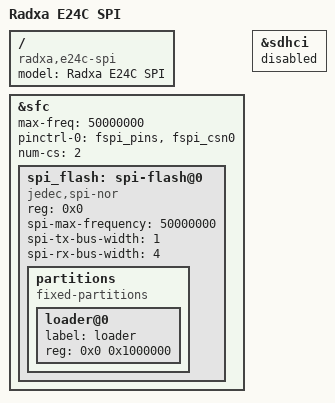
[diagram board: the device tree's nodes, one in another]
// SPDX-License-Identifier: (GPL-2.0+ OR MIT)
/*
 * Copyright (c) 2022 Rockchip Electronics Co., Ltd.
 * Copyright (c) 2024 Radxa Computer (Shenzhen) Co., Ltd.
 *
 */

// From https://github.com/radxa/kernel/blob/linux-6.1-stan-rkr5.1/arch/arm64/boot/dts/rockchip/rk3528-radxa-e24c-spi.dts @8582469f117fdfd5d1ab88fa7e4e15c3b714bf24

/dts-v1/;

#include "rk3528-radxa-e24c.dts"

/ {
	model = "Radxa E24C SPI";
	compatible = "radxa,e24c-spi", "radxa,e24c", "radxa,rock-2", "rockchip,rk3528a";
};

&sfc {
	status = "okay";
	max-freq = <50000000>;
	#address-cells = <1>;
	#size-cells = <0>;
	pinctrl-names = "default";
	pinctrl-0 = <&fspi_pins &fspi_csn0>;
	num-cs = <2>;

	spi_flash: spi-flash@0 {
		#address-cells = <1>;
		#size-cells = <0>;
		compatible = "jedec,spi-nor";
		reg = <0x0>;
		spi-max-frequency = <50000000>;
		spi-tx-bus-width = <1>;
		spi-rx-bus-width = <4>;
		status = "okay";

		partitions {
			compatible = "fixed-partitions";
			#address-cells = <1>;
			#size-cells = <1>;

			loader@0 {
				label = "loader";
				reg = <0x0 0x1000000>;
			};
		};
	};
};

&sdhci {
	status = "disabled";
};
